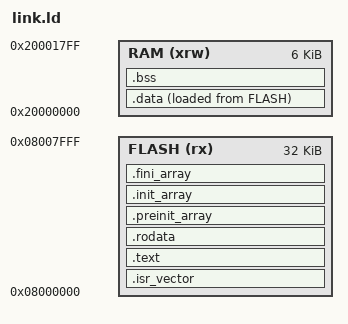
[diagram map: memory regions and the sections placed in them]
ENTRY(Reset_Handler)

MEMORY
{
  RAM    (xrw)    : ORIGIN = 0x20000000,   LENGTH = 6K
  FLASH   (rx)    : ORIGIN = 0x8000000,    LENGTH = 32K
}

SECTIONS
{
  .isr_vector :
  {
    KEEP(*(.isr_vector))
  } >FLASH

  .text :
  {
    *(.text)
    *(.text*)
  } >FLASH

  .rodata :
  {
    *(.rodata)
    *(.rodata*)
  } >FLASH

  .preinit_array (READONLY) :
  {
    PROVIDE_HIDDEN (__preinit_array_start = .);
    KEEP (*(.preinit_array*))
    PROVIDE_HIDDEN (__preinit_array_end = .);
  } >FLASH

  .init_array (READONLY) :
  {
    PROVIDE_HIDDEN (__init_array_start = .);
    KEEP (*(SORT(.init_array.*)))
    KEEP (*(.init_array*))
    PROVIDE_HIDDEN (__init_array_end = .);
  } >FLASH

  .fini_array (READONLY) :
  {
    . = ALIGN(4);
    PROVIDE_HIDDEN (__fini_array_start = .);
    KEEP (*(SORT(.fini_array.*)))
    KEEP (*(.fini_array*))
    PROVIDE_HIDDEN (__fini_array_end = .);
  } >FLASH

  .data :
  {
    _sdata = .;
    *(.data)
    *(.data*)
    _edata = .;
  } >RAM AT> FLASH

  .bss :
  {
    _sbss = .;
    *(.bss)
    *(.bss*)
    _ebss = .;
    _end = .;
  } >RAM

  _sidata = LOADADDR(.data);
  _estack = ORIGIN(RAM) + LENGTH(RAM);

  /DISCARD/ :
  {
    libc.a ( * )
    libm.a ( * )
    libgcc.a ( * )
  }
}
